# nrf9120_MLM1 register map
Vendor: Nordic Semiconductor; Series: nrf91; File version: 1
CPU: CM4 r0p1, little endian, MPU, FPU, 3 interrupt priority bits
Registers are 32-bit, read-write, reset 0x0 unless marked. A register's access mark holds for its fields unless they carry their own. Offsets are from the block's base; [hi:lo] are bit positions; lines under a group give offsets from that group; {n}, {i} and the like mark numbered series; 'fields as' and 'values as' point back to an identical list.

## PWM0 — Pulse Width Modulation Unit
Base 0x40016000
0x00 TASKS_START wo — Starts PWM pulse generation with the last loaded values
0x04 TASKS_STOP wo — Stops PWM pulse generation on all channels at the end of current PWM period, and stops sequence playback
{0x8+4i} TASKS_SEQSTART[{i}] (i=0..1) wo — Description collection[0]: Loads the first PWM value on all enabled channels from sequence 0, and starts playing that sequence at the rate defined in SEQ[0]REFRESH and/or DECODER.MODE. Causes PWM generation to start it was not running. Sending a SEQSTART[0] task while a sequence is already playing back will gracefully (i.e. glitch-free) abort that sequence at the earliest opportunity and start sequence 0.
0x10 TASKS_NEXTSTEP wo — Steps by one value in the current sequence on all enabled channels if DECODER.MODE=NextStep. Does not cause PWM generation to start it was not running.
0x14 TASKS_SEQABORT wo — (Gracefully) aborts the playback of the current sequence or the current end delay.
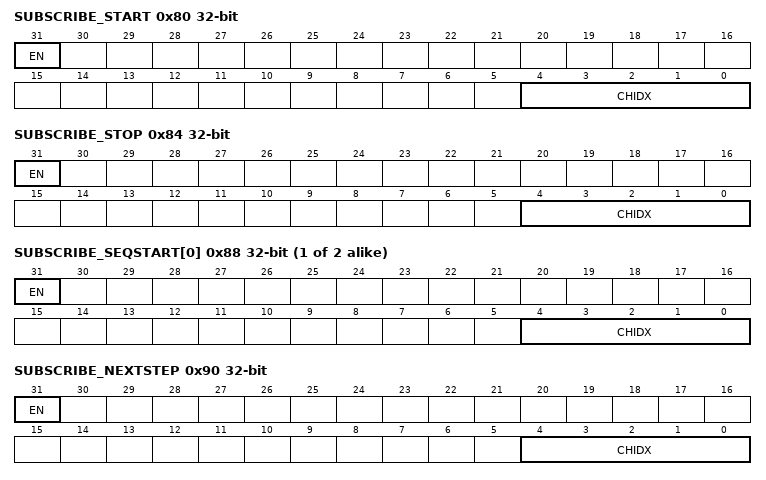
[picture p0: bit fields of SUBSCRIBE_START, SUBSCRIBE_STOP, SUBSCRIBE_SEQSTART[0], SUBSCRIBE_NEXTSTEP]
0x80 SUBSCRIBE_START — Subscribe configuration for TASKS_START
  [31] EN
    0=Disabled (Disable subscription); 1=Enabled (Enable subscription)
  [4:0] CHIDX — Channel the TASKS_START will subscribe to.
0x84 SUBSCRIBE_STOP — Subscribe configuration for TASKS_STOP
  [31] EN
    values as SUBSCRIBE_START.EN
  [4:0] CHIDX — Channel the TASKS_STOP will subscribe to.
{0x88+4i} SUBSCRIBE_SEQSTART[{i}] (i=0..1) — Description collection[0]: Subscribe configuration for TASKS_SEQSTART[0]
  [31] EN
    values as SUBSCRIBE_START.EN
  [4:0] CHIDX — Channel the TASKS_SEQSTART[0] will subscribe to.
0x90 SUBSCRIBE_NEXTSTEP — Subscribe configuration for TASKS_NEXTSTEP
  [31] EN
    values as SUBSCRIBE_START.EN
  [4:0] CHIDX — Channel the TASKS_NEXTSTEP will subscribe to.
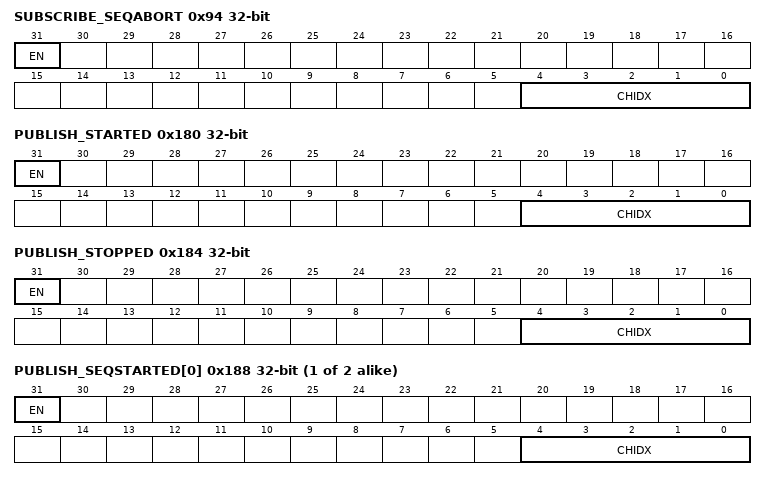
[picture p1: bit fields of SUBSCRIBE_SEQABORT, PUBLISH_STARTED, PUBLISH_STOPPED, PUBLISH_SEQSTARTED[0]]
0x94 SUBSCRIBE_SEQABORT — Subscribe configuration for TASKS_SEQABORT
  [31] EN
    values as SUBSCRIBE_START.EN
  [4:0] CHIDX — Channel the TASKS_SEQABORT will subscribe to.
0x100 EVENTS_STARTED — Response to START task, emitted when PWM pulses start to get generated
0x104 EVENTS_STOPPED — Response to STOP task, emitted when PWM pulses are no longer generated
{0x108+4i} EVENTS_SEQSTARTED[{i}] (i=0..1) — Description collection[0]: First PWM period started on sequence 0
{0x110+4i} EVENTS_SEQEND[{i}] (i=0..1) — Description collection[0]: Emitted at end of every sequence 0, when last value from RAM has been applied to wave counter
0x118 EVENTS_PWMPERIODEND — Emitted at the end of each PWM period
0x11C EVENTS_LOOPSDONE — Concatenated sequences have been played the amount of times defined in LOOP.CNT
0x120 EVENTS_RAMUNDERFLOW — Emitted when a RAM fecth does not complete in time for the PWM module
{0x124+4i} EVENTS_DMAREADY[{i}] (i=0..1) — Description collection[0]: Emitted when EasyDMA has fetched .PTR and .CNT registers for sequence 0 (they can be prepared for the next sequence)
{0x12C+4i} EVENTS_DMAEND[{i}] (i=0..1) — Description collection[0]: Emitted when EasyDMA has finished fetching values of sequence 0 from RAM buffer
0x180 PUBLISH_STARTED — Publish configuration for EVENTS_STARTED
  [31] EN
    0=Disabled (Disable publishing); 1=Enabled (Enable publishing)
  [4:0] CHIDX — Channel the EVENTS_STARTED will subscribe to.
0x184 PUBLISH_STOPPED — Publish configuration for EVENTS_STOPPED
  [31] EN
    values as PUBLISH_STARTED.EN
  [4:0] CHIDX — Channel the EVENTS_STOPPED will subscribe to.
{0x188+4i} PUBLISH_SEQSTARTED[{i}] (i=0..1) — Description collection[0]: Publish configuration for EVENTS_SEQSTARTED[0]
  [31] EN
    values as PUBLISH_STARTED.EN
  [4:0] CHIDX — Channel the EVENTS_SEQSTARTED[0] will subscribe to.
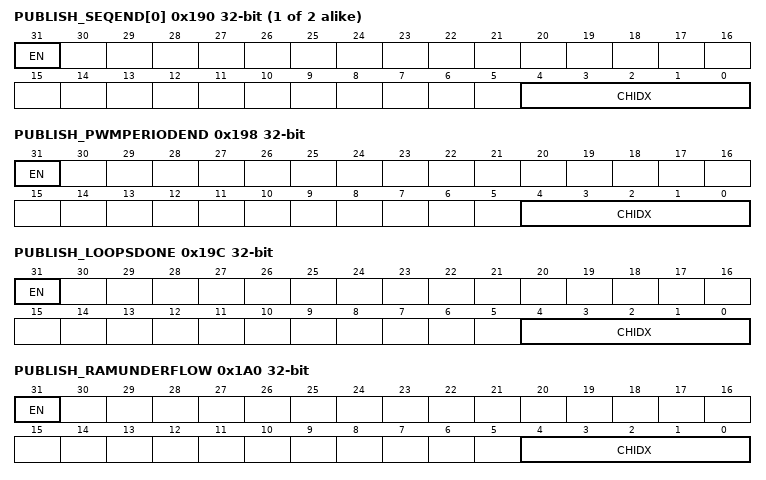
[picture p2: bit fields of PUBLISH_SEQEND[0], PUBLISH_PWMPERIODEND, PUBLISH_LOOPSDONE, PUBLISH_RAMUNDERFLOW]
{0x190+4i} PUBLISH_SEQEND[{i}] (i=0..1) — Description collection[0]: Publish configuration for EVENTS_SEQEND[0]
  [31] EN
    values as PUBLISH_STARTED.EN
  [4:0] CHIDX — Channel the EVENTS_SEQEND[0] will subscribe to.
0x198 PUBLISH_PWMPERIODEND — Publish configuration for EVENTS_PWMPERIODEND
  [31] EN
    values as PUBLISH_STARTED.EN
  [4:0] CHIDX — Channel the EVENTS_PWMPERIODEND will subscribe to.
0x19C PUBLISH_LOOPSDONE — Publish configuration for EVENTS_LOOPSDONE
  [31] EN
    values as PUBLISH_STARTED.EN
  [4:0] CHIDX — Channel the EVENTS_LOOPSDONE will subscribe to.
0x1A0 PUBLISH_RAMUNDERFLOW — Publish configuration for EVENTS_RAMUNDERFLOW
  [31] EN
    values as PUBLISH_STARTED.EN
  [4:0] CHIDX — Channel the EVENTS_RAMUNDERFLOW will subscribe to.
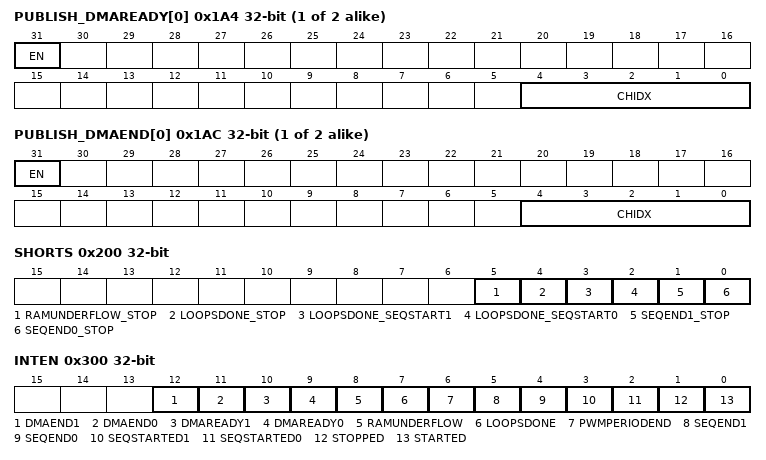
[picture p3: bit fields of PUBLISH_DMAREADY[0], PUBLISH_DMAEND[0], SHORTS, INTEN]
{0x1A4+4i} PUBLISH_DMAREADY[{i}] (i=0..1) — Description collection[0]: Publish configuration for EVENTS_DMAREADY[0]
  [31] EN
    values as PUBLISH_STARTED.EN
  [4:0] CHIDX — Channel the EVENTS_DMAREADY[0] will subscribe to.
{0x1AC+4i} PUBLISH_DMAEND[{i}] (i=0..1) — Description collection[0]: Publish configuration for EVENTS_DMAEND[0]
  [31] EN
    values as PUBLISH_STARTED.EN
  [4:0] CHIDX — Channel the EVENTS_DMAEND[0] will subscribe to.
0x200 SHORTS — Shortcut register
  [all] fields
    0=Disabled (Disable shortcut); 1=Enabled (Enable shortcut)
  [5] RAMUNDERFLOW_STOP — Shortcut between RAMUNDERFLOW event and STOP task
  [4] LOOPSDONE_STOP — Shortcut between LOOPSDONE event and STOP task
  [3] LOOPSDONE_SEQSTART1 — Shortcut between LOOPSDONE event and SEQSTART[1] task
  [2] LOOPSDONE_SEQSTART0 — Shortcut between LOOPSDONE event and SEQSTART[0] task
  [1] SEQEND1_STOP — Shortcut between SEQEND[1] event and STOP task
  [0] SEQEND0_STOP — Shortcut between SEQEND[0] event and STOP task
0x300 INTEN — Enable or disable interrupt
  [all] fields
    0=Disabled; 1=Enabled
  [12] DMAEND1 — Enable or disable interrupt for DMAEND[1] event
  [11] DMAEND0 — Enable or disable interrupt for DMAEND[0] event
  [10] DMAREADY1 — Enable or disable interrupt for DMAREADY[1] event
  [9] DMAREADY0 — Enable or disable interrupt for DMAREADY[0] event
  [8] RAMUNDERFLOW — Enable or disable interrupt for RAMUNDERFLOW event
  [7] LOOPSDONE — Enable or disable interrupt for LOOPSDONE event
  [6] PWMPERIODEND — Enable or disable interrupt for PWMPERIODEND event
  [5] SEQEND1 — Enable or disable interrupt for SEQEND[1] event
  [4] SEQEND0 — Enable or disable interrupt for SEQEND[0] event
  [3] SEQSTARTED1 — Enable or disable interrupt for SEQSTARTED[1] event
  [2] SEQSTARTED0 — Enable or disable interrupt for SEQSTARTED[0] event
  [1] STOPPED — Enable or disable interrupt for STOPPED event
  [0] STARTED — Enable or disable interrupt for STARTED event
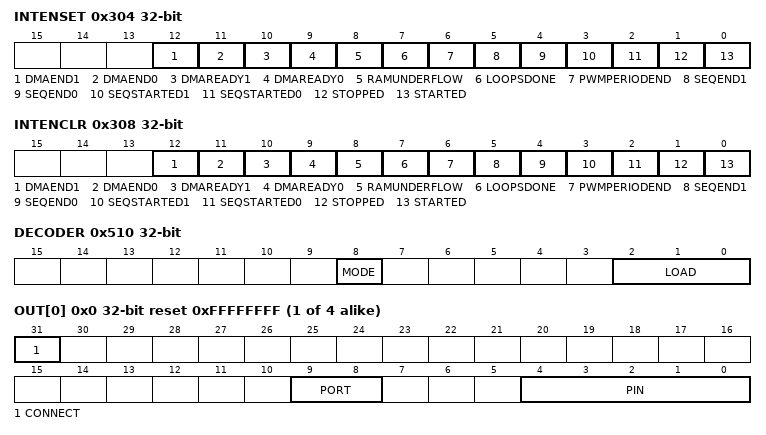
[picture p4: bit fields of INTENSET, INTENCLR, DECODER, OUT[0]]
0x304 INTENSET — Enable interrupt
  [all] fields
    on read: 0=Disabled (Read: Disabled); 1=Enabled (Read: Enabled) | on write: 1=Set (Enable)
  [12] DMAEND1 — Write '1' to Enable interrupt for DMAEND[1] event
  [11] DMAEND0 — Write '1' to Enable interrupt for DMAEND[0] event
  [10] DMAREADY1 — Write '1' to Enable interrupt for DMAREADY[1] event
  [9] DMAREADY0 — Write '1' to Enable interrupt for DMAREADY[0] event
  [8] RAMUNDERFLOW — Write '1' to Enable interrupt for RAMUNDERFLOW event
  [7] LOOPSDONE — Write '1' to Enable interrupt for LOOPSDONE event
  [6] PWMPERIODEND — Write '1' to Enable interrupt for PWMPERIODEND event
  [5] SEQEND1 — Write '1' to Enable interrupt for SEQEND[1] event
  [4] SEQEND0 — Write '1' to Enable interrupt for SEQEND[0] event
  [3] SEQSTARTED1 — Write '1' to Enable interrupt for SEQSTARTED[1] event
  [2] SEQSTARTED0 — Write '1' to Enable interrupt for SEQSTARTED[0] event
  [1] STOPPED — Write '1' to Enable interrupt for STOPPED event
  [0] STARTED — Write '1' to Enable interrupt for STARTED event
0x308 INTENCLR — Disable interrupt
  [all] fields
    on read: 0=Disabled (Read: Disabled); 1=Enabled (Read: Enabled) | on write: 1=Clear (Disable)
  [12] DMAEND1 — Write '1' to Disable interrupt for DMAEND[1] event
  [11] DMAEND0 — Write '1' to Disable interrupt for DMAEND[0] event
  [10] DMAREADY1 — Write '1' to Disable interrupt for DMAREADY[1] event
  [9] DMAREADY0 — Write '1' to Disable interrupt for DMAREADY[0] event
  [8] RAMUNDERFLOW — Write '1' to Disable interrupt for RAMUNDERFLOW event
  [7] LOOPSDONE — Write '1' to Disable interrupt for LOOPSDONE event
  [6] PWMPERIODEND — Write '1' to Disable interrupt for PWMPERIODEND event
  [5] SEQEND1 — Write '1' to Disable interrupt for SEQEND[1] event
  [4] SEQEND0 — Write '1' to Disable interrupt for SEQEND[0] event
  [3] SEQSTARTED1 — Write '1' to Disable interrupt for SEQSTARTED[1] event
  [2] SEQSTARTED0 — Write '1' to Disable interrupt for SEQSTARTED[0] event
  [1] STOPPED — Write '1' to Disable interrupt for STOPPED event
  [0] STARTED — Write '1' to Disable interrupt for STARTED event
0x500 ENABLE — PWM module enable register
  [0] ENABLE — Enable or disable PWM module
    0=Disabled; 1=Enabled
0x504 MODE — Selects operating mode of the wave counter
  [0] UPDOWN — Selects up or up and down as wave counter mode
    0=Up (Up counter - edge aligned PWM duty-cycle); 1=Up and down counter - center aligned PWM duty cycle
0x508 COUNTERTOP reset 0x3FF — Value up to which the pulse generator counter counts
  [14:0] COUNTERTOP — Value up to which the pulse generator counter counts. This register is ignored when DECODER.MODE=WaveForm and only values from RAM will be used.
0x50C PRESCALER — Configuration for PWM_CLK
  [2:0] PRESCALER — Pre-scaler of PWM_CLK
    0=DIV_1 (Divide by 1 (16MHz)); 1=DIV_2 (Divide by 2 ( 8MHz)); 2=DIV_4 (Divide by 4 ( 4MHz)); 3=DIV_8 (Divide by 8 ( 2MHz)); 4=DIV_16 (Divide by 16 ( 1MHz)); 5=DIV_32 (Divide by 32 ( 500kHz)); 6=DIV_64 (Divide by 64 ( 250kHz)); 7=DIV_128 (Divide by 128 ( 125kHz))
0x510 DECODER — Configuration of the decoder
  [8] MODE — Selects source for advancing the active sequence
    0=RefreshCount (SEQ[n].REFRESH is used to determine loading internal compare registers); 1=NEXTSTEP task causes a new value to be loaded to internal compare registers
  [2:0] LOAD — How a sequence is read from RAM and spread to the compare register
    0=Common (1st half word (16-bit) used in all PWM channels 0..3); 1=Grouped (1st half word (16-bit) used in channel 0..1; 2nd word in channel 2..3); 2=Individual (1st half word (16-bit) in ch.0; 2nd in ch.1; ...; 4th in ch.3); 3=WaveForm (1st half word (16-bit) in ch.0; 2nd in ch.1; ...; 4th in COUNTERTOP)
0x514 LOOP — Amount of playback of a loop
  [15:0] CNT — Amount of playback of pattern cycles
    0=Disabled (Looping disabled (stop at the end of the sequence))
{0x520+0x20*i} SEQ[{i}] (i=0..1) group — Unspecified
  0x00 PTR — Description cluster[0]: Beginning address in Data RAM of this sequence
    [31:0] PTR — Beginning address in Data RAM of this sequence
  0x04 CNT — Description cluster[0]: Amount of values (duty cycles) in this sequence
    [14:0] CNT — Amount of values (duty cycles) in this sequence
      0=Disabled (Sequence is disabled, and shall not be started as it is empty)
  0x08 REFRESH reset 0x1 — Description cluster[0]: Amount of additional PWM periods between samples loaded into compare register
    [23:0] CNT — Amount of additional PWM periods between samples loaded into compare register (load every REFRESH.CNT+1 PWM periods)
      0=Continuous (Update every PWM period)
  0x0C ENDDELAY — Description cluster[0]: Time added after the sequence
    [23:0] CNT — Time added after the sequence in PWM periods
0x560 PSEL group — Unspecified
  {0x0+4j} OUT[{j}] (j=0..3) reset 0xFFFFFFFF — Description collection[0]: Output pin select for PWM channel 0
    [31] CONNECT — Connection
      1=Disconnected; 0=Connected
    [9:8] PORT — Port number
    [4:0] PIN — Pin number
